# MSPM0G350X register map
Vendor: Texas Instruments; File version: This preliminary header file does not have a version number - build date: 2023-02-21 16:25:48
CPU: CM0 r0p1, little endian, MPU, no FPU, 3 interrupt priority bits
Registers are 32-bit, read-write, reset 0x0 unless marked. A register's access mark holds for its fields unless they carry their own. Offsets are from the block's base; [hi:lo] are bit positions; {n}, {i} and the like mark numbered series; 'fields as' and 'values as' point back to an identical list.

## TIMG0 — PERIPHERALREGION
Base 0x40084000
0x400 FSUB_0 — Subsciber Port 0
  [3:0] FSUB_0_CHANID — 0 = disconnected. 1-15 = connected to channelID = CHANID.
    0=FSUB_0_CHANID_UNCONNECTED (UNCONNECTED)
0x404 FSUB_1 — Subscriber Port 1
  [3:0] FSUB_1_CHANID — 0 = disconnected. 1-15 = connected to channelID = CHANID.
    0=FSUB_1_CHANID_UNCONNECTED (UNCONNECTED)
0x444 FPUB_0 — Publisher Port 0
  [3:0] FPUB_0_CHANID — 0 = disconnected. 1-15 = connected to channelID = CHANID.
    0=FPUB_0_CHANID_UNCONNECTED (UNCONNECTED)
0x448 FPUB_1 — Publisher Port 1
  [3:0] FPUB_1_CHANID — 0 = disconnected. 1-15 = connected to channelID = CHANID.
    0=FPUB_1_CHANID_UNCONNECTED (UNCONNECTED)
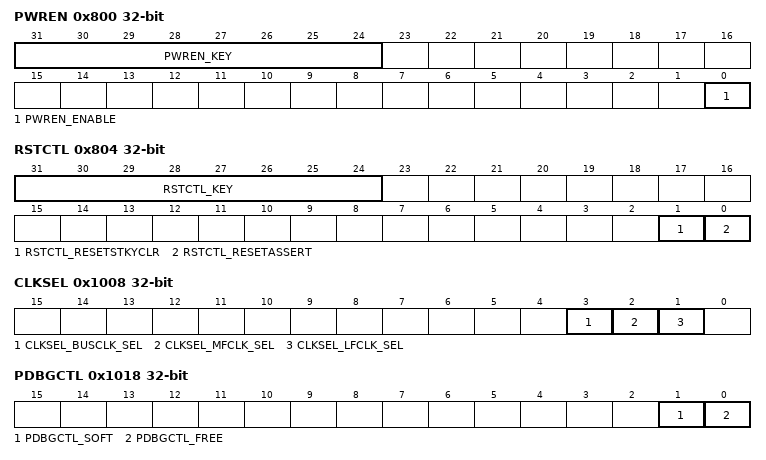
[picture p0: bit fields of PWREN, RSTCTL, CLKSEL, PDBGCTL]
0x800 PWREN — Power enable
  [31:24] PWREN_KEY wo — KEY to allow Power State Change
    38=PWREN_KEY_UNLOCK_W (_TO_UNLOCK_W_)
  [0] PWREN_ENABLE — Enable the power
    0=PWREN_ENABLE_DISABLE (DISABLE); 1=PWREN_ENABLE_ENABLE (ENABLE)
0x804 RSTCTL wo — Reset Control
  [31:24] RSTCTL_KEY — Unlock key
    177=RSTCTL_KEY_UNLOCK_W (_TO_UNLOCK_W_)
  [1] RSTCTL_RESETSTKYCLR — Clear the RESETSTKY bit in the STAT register
    0=RSTCTL_RESETSTKYCLR_NOP (NOP); 1=RSTCTL_RESETSTKYCLR_CLR (CLR)
  [0] RSTCTL_RESETASSERT — Assert reset to the peripheral
    0=RSTCTL_RESETASSERT_NOP (NOP); 1=RSTCTL_RESETASSERT_ASSERT (ASSERT)
0x814 STAT ro — Status Register
  [16] STAT_RESETSTKY — This bit indicates, if the peripheral was reset, since this bit was cleared by RESETSTKYCLR in the RSTCTL register
    0=STAT_RESETSTKY_NORES (NORES); 1=STAT_RESETSTKY_RESET (RESET)
0x1000 CLKDIV — Clock Divider
  [2:0] CLKDIV_RATIO — Selects divide ratio of module clock
    {v}=CLKDIV_RATIO_DIV_BY_{v+1} (DIV_BY_{v+1}) (v=0..7)
0x1008 CLKSEL — Clock Select for Ultra Low Power peripherals
  [3] CLKSEL_BUSCLK_SEL — Selects BUSCLK as clock source if enabled
    0=CLKSEL_BUSCLK_SEL_DISABLE (DISABLE); 1=CLKSEL_BUSCLK_SEL_ENABLE (ENABLE)
  [2] CLKSEL_MFCLK_SEL — Selects MFCLK as clock source if enabled
    0=CLKSEL_MFCLK_SEL_DISABLE (DISABLE); 1=CLKSEL_MFCLK_SEL_ENABLE (ENABLE)
  [1] CLKSEL_LFCLK_SEL — Selects LFCLK as clock source if enabled
    0=CLKSEL_LFCLK_SEL_DISABLE (DISABLE); 1=CLKSEL_LFCLK_SEL_ENABLE (ENABLE)
0x1018 PDBGCTL — Peripheral Debug Control
  [1] PDBGCTL_SOFT — Soft halt boundary control. This function is only available, if [FREE] is set to 'STOP'
    0=PDBGCTL_SOFT_IMMEDIATE (IMMEDIATE); 1=PDBGCTL_SOFT_DELAYED (DELAYED)
  [0] PDBGCTL_FREE — Free run control
    0=PDBGCTL_FREE_STOP (STOP); 1=PDBGCTL_FREE_RUN (RUN)
0x1020 IIDX ro — Interrupt index
  [7:0] IIDX_STAT — Interrupt index status
    0=IIDX_STAT_NO_INTR (NO_INTR); 1=IIDX_STAT_Z (Z); 2=IIDX_STAT_L (L); {v}=IIDX_STAT_CCD{v-5} (CCD{v-5}) (v=5..8); {v}=IIDX_STAT_CCU{v-9} (CCU{v-9}) (v=9..12); 13=IIDX_STAT_CCD4 (CCD4); 14=IIDX_STAT_CCD5 (CCD5); 15=IIDX_STAT_CCU4 (CCU4); 16=IIDX_STAT_CCU5 (CCU5); 25=IIDX_STAT_F (F); 26=IIDX_STAT_TOV (TOV); 27=IIDX_STAT_REPC (REPC); 28=IIDX_STAT_DC (DC); 29=IIDX_STAT_QEIERR (QEIERR)
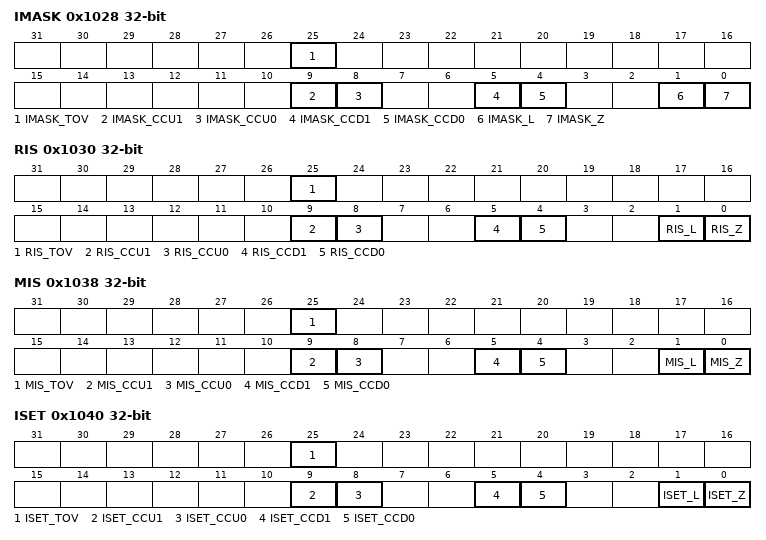
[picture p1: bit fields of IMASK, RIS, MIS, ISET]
0x1028 IMASK — Interrupt mask
  [25] IMASK_TOV — Trigger Overflow Event mask
    0=IMASK_TOV_CLR (CLR); 1=IMASK_TOV_SET (SET)
  [9] IMASK_CCU1 — Capture or Compare UP event mask CCP1
    0=IMASK_CCU1_CLR (CLR); 1=IMASK_CCU1_SET (SET)
  [8] IMASK_CCU0 — Capture or Compare UP event mask CCP0
    0=IMASK_CCU0_CLR (CLR); 1=IMASK_CCU0_SET (SET)
  [5] IMASK_CCD1 — Capture or Compare DN event mask CCP1
    0=IMASK_CCD1_CLR (CLR); 1=IMASK_CCD1_SET (SET)
  [4] IMASK_CCD0 — Capture or Compare DN event mask CCP0
    0=IMASK_CCD0_CLR (CLR); 1=IMASK_CCD0_SET (SET)
  [1] IMASK_L — Load Event mask
    0=IMASK_L_CLR (CLR); 1=IMASK_L_SET (SET)
  [0] IMASK_Z — Zero Event mask
    0=IMASK_Z_CLR (CLR); 1=IMASK_Z_SET (SET)
0x1030 RIS ro — Raw interrupt status
  [25] RIS_TOV — Trigger overflow
    0=RIS_TOV_CLR (CLR); 1=RIS_TOV_SET (SET)
  [9] RIS_CCU1 — Capture or compare up event generated an interrupt CCP1
    0=RIS_CCU1_CLR (CLR); 1=RIS_CCU1_SET (SET)
  [8] RIS_CCU0 — Capture or compare up event generated an interrupt CCP0
    0=RIS_CCU0_CLR (CLR); 1=RIS_CCU0_SET (SET)
  [5] RIS_CCD1 — Capture or compare down event generated an interrupt CCP1
    0=RIS_CCD1_CLR (CLR); 1=RIS_CCD1_SET (SET)
  [4] RIS_CCD0 — Capture or compare down event generated an interrupt CCP0
    0=RIS_CCD0_CLR (CLR); 1=RIS_CCD0_SET (SET)
  [1] RIS_L — Load event generated an interrupt.
    0=RIS_L_CLR (CLR); 1=RIS_L_SET (SET)
  [0] RIS_Z — Zero event generated an interrupt.
    0=RIS_Z_CLR (CLR); 1=RIS_Z_SET (SET)
0x1038 MIS ro — Masked interrupt status
  [25] MIS_TOV — Trigger overflow
    0=MIS_TOV_CLR (CLR); 1=MIS_TOV_SET (SET)
  [9] MIS_CCU1 — Capture or compare up event generated an interrupt CCP1
    0=MIS_CCU1_CLR (CLR); 1=MIS_CCU1_SET (SET)
  [8] MIS_CCU0 — Capture or compare up event generated an interrupt CCP0
    0=MIS_CCU0_CLR (CLR); 1=MIS_CCU0_SET (SET)
  [5] MIS_CCD1 — Capture or compare down event generated an interrupt CCP1
    0=MIS_CCD1_CLR (CLR); 1=MIS_CCD1_SET (SET)
  [4] MIS_CCD0 — Capture or compare down event generated an interrupt CCP0
    0=MIS_CCD0_CLR (CLR); 1=MIS_CCD0_SET (SET)
  [1] MIS_L — Load event generated an interrupt.
    0=MIS_L_CLR (CLR); 1=MIS_L_SET (SET)
  [0] MIS_Z — Zero event generated an interrupt.
    0=MIS_Z_CLR (CLR); 1=MIS_Z_SET (SET)
0x1040 ISET wo — Interrupt set
  [25] ISET_TOV — Trigger Overflow event SET
    0=ISET_TOV_NO_EFFECT (NO_EFFECT); 1=ISET_TOV_SET (SET)
  [9] ISET_CCU1 — Capture or compare up event SET
    0=ISET_CCU1_NO_EFFECT (NO_EFFECT); 1=ISET_CCU1_SET (SET)
  [8] ISET_CCU0 — Capture or compare up event SET
    0=ISET_CCU0_NO_EFFECT (NO_EFFECT); 1=ISET_CCU0_SET (SET)
  [5] ISET_CCD1 — Capture or compare down event SET
    0=ISET_CCD1_NO_EFFECT (NO_EFFECT); 1=ISET_CCD1_SET (SET)
  [4] ISET_CCD0 — Capture or compare down event SET
    0=ISET_CCD0_NO_EFFECT (NO_EFFECT); 1=ISET_CCD0_SET (SET)
  [1] ISET_L — Load event SET
    0=ISET_L_NO_EFFECT (NO_EFFECT); 1=ISET_L_SET (SET)
  [0] ISET_Z — Zero event SET
    0=ISET_Z_NO_EFFECT (NO_EFFECT); 1=ISET_Z_SET (SET)
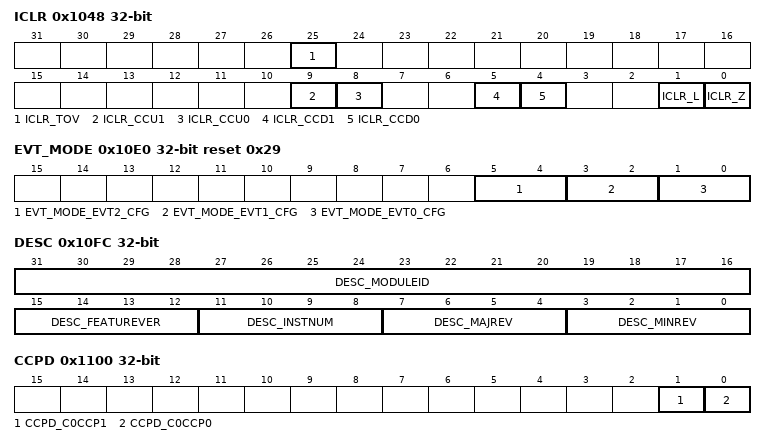
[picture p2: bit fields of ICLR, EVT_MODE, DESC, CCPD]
0x1048 ICLR wo — Interrupt clear
  [25] ICLR_TOV — Trigger Overflow event CLEAR
    0=ICLR_TOV_NO_EFFECT (NO_EFFECT); 1=ICLR_TOV_CLR (CLR)
  [9] ICLR_CCU1 — Capture or compare up event CLEAR
    0=ICLR_CCU1_NO_EFFECT (NO_EFFECT); 1=ICLR_CCU1_CLR (CLR)
  [8] ICLR_CCU0 — Capture or compare up event CLEAR
    0=ICLR_CCU0_NO_EFFECT (NO_EFFECT); 1=ICLR_CCU0_CLR (CLR)
  [5] ICLR_CCD1 — Capture or compare down event CLEAR
    0=ICLR_CCD1_NO_EFFECT (NO_EFFECT); 1=ICLR_CCD1_CLR (CLR)
  [4] ICLR_CCD0 — Capture or compare down event CLEAR
    0=ICLR_CCD0_NO_EFFECT (NO_EFFECT); 1=ICLR_CCD0_CLR (CLR)
  [1] ICLR_L — Load event CLEAR
    0=ICLR_L_NO_EFFECT (NO_EFFECT); 1=ICLR_L_CLR (CLR)
  [0] ICLR_Z — Zero event CLEAR
    0=ICLR_Z_NO_EFFECT (NO_EFFECT); 1=ICLR_Z_CLR (CLR)
0x10E0 EVT_MODE reset 0x29 — Event Mode
  [5:4] EVT_MODE_EVT2_CFG ro — Event line mode select for event corresponding to [IPSTANDARD.INT_EVENT][1]
    0=EVT_MODE_EVT2_CFG_DISABLE (DISABLE); 1=EVT_MODE_EVT2_CFG_SOFTWARE (SOFTWARE); 2=EVT_MODE_EVT2_CFG_HARDWARE (HARDWARE)
  [3:2] EVT_MODE_EVT1_CFG ro — Event line mode select for event corresponding to [IPSTANDARD.INT_EVENT][1]
    0=EVT_MODE_EVT1_CFG_DISABLE (DISABLE); 1=EVT_MODE_EVT1_CFG_SOFTWARE (SOFTWARE); 2=EVT_MODE_EVT1_CFG_HARDWARE (HARDWARE)
  [1:0] EVT_MODE_EVT0_CFG ro — Event line mode select for event corresponding to [IPSTANDARD.INT_EVENT][0]
    0=EVT_MODE_EVT0_CFG_DISABLE (DISABLE); 1=EVT_MODE_EVT0_CFG_SOFTWARE (SOFTWARE); 2=EVT_MODE_EVT0_CFG_HARDWARE (HARDWARE)
0x10FC DESC ro — Module Description
  [31:16] DESC_MODULEID — Module identification contains a unique peripheral identification number. The assignments are maintained in a central database for all of the platform modules to ensure uniqueness.
  [15:12] DESC_FEATUREVER — Feature Set for the module *instance*
  [11:8] DESC_INSTNUM — Instance Number within the device. This will be a parameter to the RTL for modules that can have multiple instances
  [7:4] DESC_MAJREV — Major rev of the IP
  [3:0] DESC_MINREV — Minor rev of the IP
0x1100 CCPD — CCP Direction
  [1] CCPD_C0CCP1 — Counter CCP1
    0=CCPD_C0CCP1_INPUT (INPUT); 1=CCPD_C0CCP1_OUTPUT (OUTPUT)
  [0] CCPD_C0CCP0 — Counter CCP0
    0=CCPD_C0CCP0_INPUT (INPUT); 1=CCPD_C0CCP0_OUTPUT (OUTPUT)
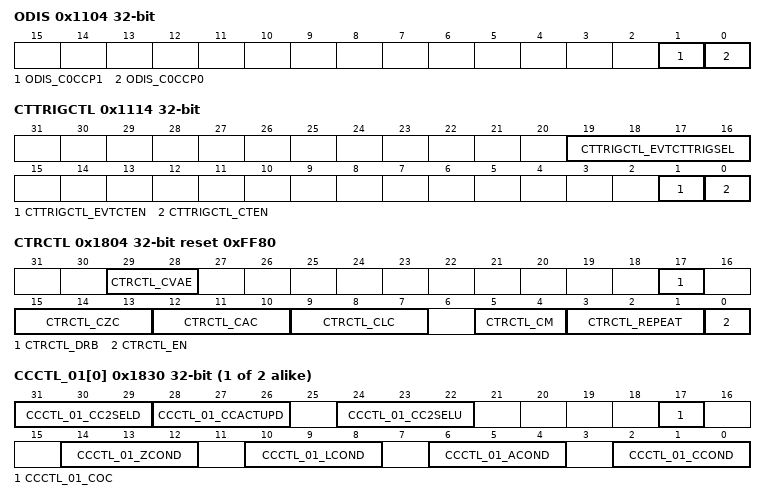
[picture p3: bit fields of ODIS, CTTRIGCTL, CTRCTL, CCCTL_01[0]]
0x1104 ODIS — Output Disable
  [1] ODIS_C0CCP1 — Counter CCP1 Disable Mask Defines whether CCP0 of Counter n is forced low or not
    0=ODIS_C0CCP1_CCP_OUTPUT_OCTL (CCP_OUTPUT_OCTL); 1=ODIS_C0CCP1_CCP_OUTPUT_LOW (CCP_OUTPUT_LOW)
  [0] ODIS_C0CCP0 — Counter CCP0 Disable Mask Defines whether CCP0 of Counter n is forced low or not
    0=ODIS_C0CCP0_CCP_OUTPUT_OCTL (CCP_OUTPUT_OCTL); 1=ODIS_C0CCP0_CCP_OUTPUT_LOW (CCP_OUTPUT_LOW)
0x1108 CCLKCTL — Counter Clock Control Register
  [0] CCLKCTL_CLKEN — Clock Enable Disables the clock gating to the module. SW has to explicitly program the value to 0 to gate the clock.
    0=CCLKCTL_CLKEN_DISABLED (DISABLED); 1=CCLKCTL_CLKEN_ENABLED (ENABLED)
0x110C CPS — Clock Prescale Register
  [7:0] CPS_PCNT — Pre-Scale Count This field specifies the pre-scale count value. The selected TIMCLK source is divided by a value of (PCNT+1). A PCNT value of 0 divides TIMCLK by 1, effectively bypassing the divider. A PCNT value of greater than 0 divides the TIMCLK source generating a slower clock
0x1110 CPSV ro — Clock prescale count status register
  [7:0] CPSV_CPSVAL — Current Prescale Count Value
0x1114 CTTRIGCTL — Timer Cross Trigger Control Register
  [19:16] CTTRIGCTL_EVTCTTRIGSEL — Used to Select the subscriber port that should be used for input cross trigger. Refer Figure 8 Cross Trigger Generation Path
    0=CTTRIGCTL_EVTCTTRIGSEL_FSUB0 (FSUB0); 1=CTTRIGCTL_EVTCTTRIGSEL_FSUB1 (FSUB1); 2=CTTRIGCTL_EVTCTTRIGSEL_Z (Z); 3=CTTRIGCTL_EVTCTTRIGSEL_L (L); {v}=CTTRIGCTL_EVTCTTRIGSEL_CCD{v-4} (CCD{v-4}) (v=4..7); {v}=CTTRIGCTL_EVTCTTRIGSEL_CCU{v-8} (CCU{v-8}) (v=8..11)
  [1] CTTRIGCTL_EVTCTEN — Enable the Input Trigger Conditions to the Timer module as a condition for Cross Triggers. Refer Figure 8 Cross Trigger Generation Path
    0=CTTRIGCTL_EVTCTEN_DISABLED (DISABLED); 1=CTTRIGCTL_EVTCTEN_ENABLE (ENABLE)
  [0] CTTRIGCTL_CTEN — Timer Cross trigger enable. This field is used to enable whether the SW or HW logic can generate a timer cross trigger event in the system. These cross triggers are connected to the respective timer trigger in of the other timer IPs in the SOC power domain. The timer cross trigger is essentially the combined logic of the HW and SW conditions controlling EN bit in the CTRCTL register.
    0=CTTRIGCTL_CTEN_DISABLED (DISABLED); 1=CTTRIGCTL_CTEN_ENABLE (ENABLE)
0x111C CTTRIG wo — Timer Cross Trigger Register
  [0] CTTRIG_TRIG — Generate Cross Trigger This bit when programmed will generate a synchronized trigger condition all the cross trigger enabled Timer instances including current timer instance.
    0=CTTRIG_TRIG_DISABLED (DISABLED); 1=CTTRIG_TRIG_GENERATE (GENERATE)
0x1800 CTR — Counter Register
  [15:0] CTR_CCTR — Current Counter value
0x1804 CTRCTL reset 0xFF80 — Counter Control Register
  [29:28] CTRCTL_CVAE — Counter Value After Enable. This field specifies the initialization condition of the counter when the EN bit is changed from 0 to 1 by a write to the CTRCTL register. Note that an external event can also cause the EN bit to go active.
    0=CTRCTL_CVAE_LDVAL (LDVAL); 1=CTRCTL_CVAE_NOCHANGE (NOCHANGE); 2=CTRCTL_CVAE_ZEROVAL (ZEROVAL)
  [17] CTRCTL_DRB — Debug Resume Behavior This bit specifies what the device does following the release/exit of debug mode.
    0=CTRCTL_DRB_RESUME (RESUME); 1=CTRCTL_DRB_CVAE_ACTION (CVAE_ACTION)
  [15:13] CTRCTL_CZC — Counter Zero Control This field specifies what controls the counter operation with respect to zeroing the counter value. Encodings 1-3 are present based on the CCPC parameter value. Bits 4-5 are present based on the HQEI parameter value. Any encodings not provided are documented as reserved.
    {v}=CTRCTL_CZC_CCCTL{v}_ZCOND (CCCTL{v}_ZCOND) (v=0..3); 4=CTRCTL_CZC_QEI_2INP (QEI_2INP); 5=CTRCTL_CZC_QEI_3INP (QEI_3INP)
  [12:10] CTRCTL_CAC — Counter Advance Control. This field specifies what controls the counter operation with respect to advancing (incrementing or decrementing) the counter value. Encodings 1-3 are present based on the CCPC parameter value. Bits 4-5 are present based on the HQEI parameter value. Any encodings not provided are documented as reserved.
    {v}=CTRCTL_CAC_CCCTL{v}_ACOND (CCCTL{v}_ACOND) (v=0..3); 4=CTRCTL_CAC_QEI_2INP (QEI_2INP); 5=CTRCTL_CAC_QEI_3INP (QEI_3INP)
  [9:7] CTRCTL_CLC — Counter Load Control. This field specifies what controls the counter operation with respect to setting the counter to the LD register value. Encodings 1-3 are present based on the CCPC parameter value. Bits 4-5 are present based on the HQEI parameter value. Any encodings not provided are documented as reserved.
    {v}=CTRCTL_CLC_CCCTL{v}_LCOND (CCCTL{v}_LCOND) (v=0..3); 4=CTRCTL_CLC_QEI_2INP (QEI_2INP); 5=CTRCTL_CLC_QEI_3INP (QEI_3INP)
  [5:4] CTRCTL_CM — Count Mode
    0=CTRCTL_CM_DOWN (DOWN); 1=CTRCTL_CM_UP_DOWN (UP_DOWN); 2=CTRCTL_CM_UP (UP)
  [3:1] CTRCTL_REPEAT — Repeat. The repeat bit controls whether the counter continues to advance following a zero event, or the exiting of a debug or fault condition. If counting down, a zero event is followed by a load at the next advance condition. If counting up-down, a zero event is followed by an advance event (+1). The intent of encoding 3 is that if the debug condition is in effect, the generation of the load pulse is deferred until the debug condition is over. This allows the counter to reach zero before counting is suspended.
    {v}=CTRCTL_REPEAT_REPEAT_{v} (REPEAT_{v}) (v=0..4)
  [0] CTRCTL_EN — Counter Enable. This bit allows the timer to advance This bit is automatically cleared if REPEAT=0 (do not automatically reload) and the counter value equals zero. CPU Write: A register write that sets the EN bit, the counter value is set per the CVAE value. Hardware: This bit may also be set as the result of an LCOND or ZCOND condition being met and the counter value changed to the load value or zero value, respectively.
    0=CTRCTL_EN_DISABLED (DISABLED); 1=CTRCTL_EN_ENABLED (ENABLED)
0x1808 LOAD
  [15:0] LOAD_LD — Load Value
{0x1810+4i} CC_01[{i}] (i=0..1) — Capture or Compare Register 0 to Capture or Compare Register 1
  [15:0] CC_01_CCVAL — Capture or compare value
{0x1830+4i} CCCTL_01[{i}] (i=0..1) — Capture or Compare Control Registers
  [31:29] CCCTL_01_CC2SELD — Selects the source second CCD event.
    {v}=CCCTL_01_CC2SELD_SEL_CCD{v} (SEL_CCD{v}) (v=0..5)
  [28:26] CCCTL_01_CCACTUPD — CCACT shadow register Update Method This field controls how updates to the CCCACT shadow register are performed
    0=CCCTL_01_CCACTUPD_IMMEDIATELY (IMMEDIATELY); 1=CCCTL_01_CCACTUPD_ZERO_EVT (ZERO_EVT); 2=CCCTL_01_CCACTUPD_COMPARE_DOWN_EVT (COMPARE_DOWN_EVT); 3=CCCTL_01_CCACTUPD_COMPARE_UP_EVT (COMPARE_UP_EVT); 4=CCCTL_01_CCACTUPD_ZERO_LOAD_EVT (ZERO_LOAD_EVT); 5=CCCTL_01_CCACTUPD_ZERO_RC_ZERO_EVT (ZERO_RC_ZERO_EVT); 6=CCCTL_01_CCACTUPD_TRIG (TRIG)
  [24:22] CCCTL_01_CC2SELU — Selects the source second CCU event.
    {v}=CCCTL_01_CC2SELU_SEL_CCU{v} (SEL_CCU{v}) (v=0..5)
  [17] CCCTL_01_COC — Capture or Compare. #br# Specifies whether the corresponding CC register is used as a capture register or a compare register (never both).
    0=CCCTL_01_COC_COMPARE (COMPARE); 1=CCCTL_01_COC_CAPTURE (CAPTURE)
  [14:12] CCCTL_01_ZCOND — Zero Condition. #br# This field specifies the condition that generates a zero pulse. 4h-Fh = Reserved
    1=CCCTL_01_ZCOND_CC_TRIG_RISE (CC_TRIG_RISE); 2=CCCTL_01_ZCOND_CC_TRIG_FALL (CC_TRIG_FALL); 3=CCCTL_01_ZCOND_CC_TRIG_EDGE (CC_TRIG_EDGE)
  [10:8] CCCTL_01_LCOND — Load Condition. #br# Specifies the condition that generates a load pulse. 4h-Fh = Reserved
    1=CCCTL_01_LCOND_CC_TRIG_RISE (CC_TRIG_RISE); 2=CCCTL_01_LCOND_CC_TRIG_FALL (CC_TRIG_FALL); 3=CCCTL_01_LCOND_CC_TRIG_EDGE (CC_TRIG_EDGE)
  [6:4] CCCTL_01_ACOND — Advance Condition. #br# Specifies the condition that generates an advance pulse. 6h-Fh = Reserved
    0=CCCTL_01_ACOND_TIMCLK (TIMCLK); 1=CCCTL_01_ACOND_CC_TRIG_RISE (CC_TRIG_RISE); 2=CCCTL_01_ACOND_CC_TRIG_FALL (CC_TRIG_FALL); 3=CCCTL_01_ACOND_CC_TRIG_EDGE (CC_TRIG_EDGE); 5=CCCTL_01_ACOND_CC_TRIG_HIGH (CC_TRIG_HIGH)
  [2:0] CCCTL_01_CCOND — Capture Condition. #br# Specifies the condition that generates a capture pulse. 4h-Fh = Reserved
    0=CCCTL_01_CCOND_NOCAPTURE (NOCAPTURE); 1=CCCTL_01_CCOND_CC_TRIG_RISE (CC_TRIG_RISE); 2=CCCTL_01_CCOND_CC_TRIG_FALL (CC_TRIG_FALL); 3=CCCTL_01_CCOND_CC_TRIG_EDGE (CC_TRIG_EDGE)
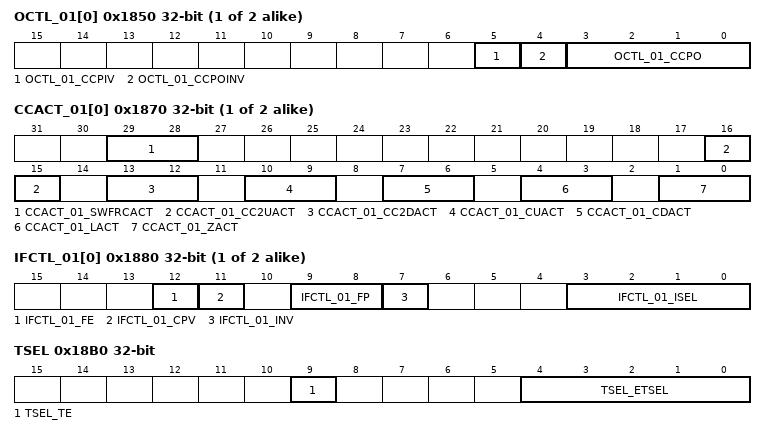
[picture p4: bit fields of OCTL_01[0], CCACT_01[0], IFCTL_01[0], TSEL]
{0x1850+4i} OCTL_01[{i}] (i=0..1) — CCP Output Control Registers
  [5] OCTL_01_CCPIV — CCP Initial Value This bit specifies the logical value put on the signal generator state while the counter is disabled (CTRCTL.EN == 0).
    0=OCTL_01_CCPIV_LOW (LOW); 1=OCTL_01_CCPIV_HIGH (HIGH)
  [4] OCTL_01_CCPOINV — CCP Output Invert The output as selected by CCPO is conditionally inverted.
    0=OCTL_01_CCPOINV_NOINV (NOINV); 1=OCTL_01_CCPOINV_INV (INV)
  [3:0] OCTL_01_CCPO — CCP Output Source
    0=OCTL_01_CCPO_FUNCVAL (FUNCVAL); 1=OCTL_01_CCPO_LOAD (LOAD); 2=OCTL_01_CCPO_CMPVAL (CMPVAL); 4=OCTL_01_CCPO_ZERO (ZERO); 5=OCTL_01_CCPO_CAPCOND (CAPCOND); 6=OCTL_01_CCPO_FAULTCOND (FAULTCOND); 8=OCTL_01_CCPO_CC0_MIRROR_ALL (CC0_MIRROR_ALL); 9=OCTL_01_CCPO_CC1_MIRROR_ALL (CC1_MIRROR_ALL); 12=OCTL_01_CCPO_DEADBAND (DEADBAND); 13=OCTL_01_CCPO_CNTDIR (CNTDIR)
{0x1870+4i} CCACT_01[{i}] (i=0..1) — Capture or Compare Action Registers
  [29:28] CCACT_01_SWFRCACT — CCP Output Action on Software Froce Output This field describes the resulting action of software force. This action has a shadow register, which will be updated under specific condition. So that this register cannot take into effect immediately.
    0=CCACT_01_SWFRCACT_DISABLED (DISABLED); 1=CCACT_01_SWFRCACT_CCP_HIGH (CCP_HIGH); 2=CCACT_01_SWFRCACT_CCP_LOW (CCP_LOW)
  [16:15] CCACT_01_CC2UACT — CCP Output Action on CC2U event.
    0=CCACT_01_CC2UACT_DISABLED (DISABLED); 1=CCACT_01_CC2UACT_CCP_HIGH (CCP_HIGH); 2=CCACT_01_CC2UACT_CCP_LOW (CCP_LOW); 3=CCACT_01_CC2UACT_CCP_TOGGLE (CCP_TOGGLE)
  [13:12] CCACT_01_CC2DACT — CCP Output Action on CC2D event.
    0=CCACT_01_CC2DACT_DISABLED (DISABLED); 1=CCACT_01_CC2DACT_CCP_HIGH (CCP_HIGH); 2=CCACT_01_CC2DACT_CCP_LOW (CCP_LOW); 3=CCACT_01_CC2DACT_CCP_TOGGLE (CCP_TOGGLE)
  [10:9] CCACT_01_CUACT — CCP Output Action on Compare (Up) This field describes the resulting action of the signal generator upon detecting a compare event while counting up.
    0=CCACT_01_CUACT_DISABLED (DISABLED); 1=CCACT_01_CUACT_CCP_HIGH (CCP_HIGH); 2=CCACT_01_CUACT_CCP_LOW (CCP_LOW); 3=CCACT_01_CUACT_CCP_TOGGLE (CCP_TOGGLE)
  [7:6] CCACT_01_CDACT — CCP Output Action on Compare (Down) This field describes the resulting action of the signal generator upon detecting a compare event while counting down.
    0=CCACT_01_CDACT_DISABLED (DISABLED); 1=CCACT_01_CDACT_CCP_HIGH (CCP_HIGH); 2=CCACT_01_CDACT_CCP_LOW (CCP_LOW); 3=CCACT_01_CDACT_CCP_TOGGLE (CCP_TOGGLE)
  [4:3] CCACT_01_LACT — CCP Output Action on Load Specifies what changes occur to CCP output as the result of a load event.
    0=CCACT_01_LACT_DISABLED (DISABLED); 1=CCACT_01_LACT_CCP_HIGH (CCP_HIGH); 2=CCACT_01_LACT_CCP_LOW (CCP_LOW); 3=CCACT_01_LACT_CCP_TOGGLE (CCP_TOGGLE)
  [1:0] CCACT_01_ZACT — CCP Output Action on Zero Specifies what changes occur to CCP output as the result of a zero event.
    0=CCACT_01_ZACT_DISABLED (DISABLED); 1=CCACT_01_ZACT_CCP_HIGH (CCP_HIGH); 2=CCACT_01_ZACT_CCP_LOW (CCP_LOW); 3=CCACT_01_ZACT_CCP_TOGGLE (CCP_TOGGLE)
{0x1880+4i} IFCTL_01[{i}] (i=0..1) — Input Filter Control Register
  [12] IFCTL_01_FE — Filter Enable This bit controls whether the input is filtered by the input filter or bypasses to the edge detect.
    0=IFCTL_01_FE_DISABLED (DISABLED); 1=IFCTL_01_FE_ENABLED (ENABLED)
  [11] IFCTL_01_CPV — Consecutive Period/Voting Select This bit controls whether the input filter uses a stricter consecutive period count or majority voting.
    0=IFCTL_01_CPV_CONSECUTIVE (CONSECUTIVE); 1=IFCTL_01_CPV_VOTING (VOTING)
  [9:8] IFCTL_01_FP — Filter Period. This field specifies the sample period for the input filter. I.e. The input is sampled for FP timer clocks during filtering.
    0=IFCTL_01_FP__3 (_3); 1=IFCTL_01_FP__5 (_5); 2=IFCTL_01_FP__8 (_8)
  [7] IFCTL_01_INV — Input Inversion This bit controls whether the selected input is inverted.
    0=IFCTL_01_INV_NOINVERT (NOINVERT); 1=IFCTL_01_INV_INVERT (INVERT)
  [3:0] IFCTL_01_ISEL — Input Select (CCP0) This field selects the input source to the filter input. 4h-7h = Reserved
    0=IFCTL_01_ISEL_CCPX_INPUT (CCPX_INPUT); 1=IFCTL_01_ISEL_CCPX_INPUT_PAIR (CCPX_INPUT_PAIR); 2=IFCTL_01_ISEL_CCP0_INPUT (CCP0_INPUT); 3=IFCTL_01_ISEL_TRIG_INPUT (TRIG_INPUT); 4=IFCTL_01_ISEL_CCP_XOR (CCP_XOR); 5=IFCTL_01_ISEL_FSUB0 (FSUB0); 6=IFCTL_01_ISEL_FSUB1 (FSUB1); 7=IFCTL_01_ISEL_COMP0 (COMP0); 8=IFCTL_01_ISEL_COMP1 (COMP1); 9=IFCTL_01_ISEL_COMP2 (COMP2)
0x18B0 TSEL — Trigger Select
  [9] TSEL_TE — Trigger Enable. This selects whether a trigger is enabled or not for this counter 0x0 = Triggers are not used 0x1 = Triggers are used as selected by the ETSEL field
    0=TSEL_TE_DISABLED (DISABLED); 1=TSEL_TE_ENABLED (ENABLED)
  [4:0] TSEL_ETSEL — External Trigger Select. #br# This selects which System Event is used if the input filter selects trigger. Triggers 0-15 are used to connect triggers generated by other timer modules in the same power domain. Refer to the SoC datasheet to get details. Triggers 16 and 17 are connected to event manager subscriber ports. Event lines 18-31 are reserved for future use.
    {v}=TSEL_ETSEL_TRIG{v} (TRIG{v}) (v=0..15); 16=TSEL_ETSEL_TRIG_SUB0 (TRIG_SUB0); 17=TSEL_ETSEL_TRIG_SUB1 (TRIG_SUB1)

## TIMG12 — PERIPHERALREGION
Base 0x40870000
Registers as TIMG0, without CPS, CPSV; these are added or differ:
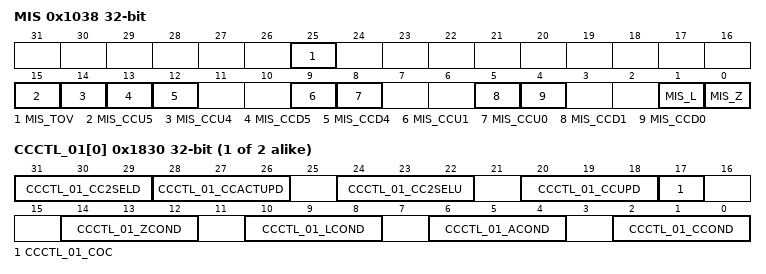
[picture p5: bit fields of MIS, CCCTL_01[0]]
0x1038 MIS ro — Masked interrupt status
  [25] MIS_TOV — Trigger overflow
    0=MIS_TOV_CLR (CLR); 1=MIS_TOV_SET (SET)
  [15] MIS_CCU5 — Compare up event generated an interrupt CCP5
    0=MIS_CCU5_CLR (CLR); 1=MIS_CCU5_SET (SET)
  [14] MIS_CCU4 — Compare up event generated an interrupt CCP4
    0=MIS_CCU4_CLR (CLR); 1=MIS_CCU4_SET (SET)
  [13] MIS_CCD5 — Compare down event generated an interrupt CCP5
    0=MIS_CCD5_CLR (CLR); 1=MIS_CCD5_SET (SET)
  [12] MIS_CCD4 — Compare down event generated an interrupt CCP4
    0=MIS_CCD4_CLR (CLR); 1=MIS_CCD4_SET (SET)
  [9] MIS_CCU1 — Capture or compare up event generated an interrupt CCP1
    0=MIS_CCU1_CLR (CLR); 1=MIS_CCU1_SET (SET)
  [8] MIS_CCU0 — Capture or compare up event generated an interrupt CCP0
    0=MIS_CCU0_CLR (CLR); 1=MIS_CCU0_SET (SET)
  [5] MIS_CCD1 — Capture or compare down event generated an interrupt CCP1
    0=MIS_CCD1_CLR (CLR); 1=MIS_CCD1_SET (SET)
  [4] MIS_CCD0 — Capture or compare down event generated an interrupt CCP0
    0=MIS_CCD0_CLR (CLR); 1=MIS_CCD0_SET (SET)
  [1] MIS_L — Load event generated an interrupt.
    0=MIS_L_CLR (CLR); 1=MIS_L_SET (SET)
  [0] MIS_Z — Zero event generated an interrupt.
    0=MIS_Z_CLR (CLR); 1=MIS_Z_SET (SET)
0x1800 CTR — Counter Register
  [31:0] CTR_CCTR — Current Counter value
0x1808 LOAD
  [31:0] LOAD_LD — Load Value
{0x1810+4i} CC_01[{i}] (i=0..1) — Capture or Compare Register 0 to Capture or Compare Register 1
  [31:0] CC_01_CCVAL — Capture or compare value
{0x1830+4i} CCCTL_01[{i}] (i=0..1) — Capture or Compare Control Registers
  [31:29] CCCTL_01_CC2SELD — Selects the source second CCD event.
    {v}=CCCTL_01_CC2SELD_SEL_CCD{v} (SEL_CCD{v}) (v=0..5)
  [28:26] CCCTL_01_CCACTUPD — CCACT shadow register Update Method This field controls how updates to the CCCACT shadow register are performed
    values as TIMG0.CCCTL_01[0].CCCTL_01_CCACTUPD
  [24:22] CCCTL_01_CC2SELU — Selects the source second CCU event.
    {v}=CCCTL_01_CC2SELU_SEL_CCU{v} (SEL_CCU{v}) (v=0..5)
  [20:18] CCCTL_01_CCUPD — Capture and Compare Update Method This field controls how updates to the pipelined capture and compare register are performed (when operating in compare mode, COC=0).
    0=CCCTL_01_CCUPD_IMMEDIATELY (IMMEDIATELY); 1=CCCTL_01_CCUPD_ZERO_EVT (ZERO_EVT); 2=CCCTL_01_CCUPD_COMPARE_DOWN_EVT (COMPARE_DOWN_EVT); 3=CCCTL_01_CCUPD_COMPARE_UP_EVT (COMPARE_UP_EVT); 4=CCCTL_01_CCUPD_ZERO_LOAD_EVT (ZERO_LOAD_EVT); 5=CCCTL_01_CCUPD_ZERO_RC_ZERO_EVT (ZERO_RC_ZERO_EVT); 6=CCCTL_01_CCUPD_TRIG (TRIG)
  [17] CCCTL_01_COC — Capture or Compare. #br# Specifies whether the corresponding CC register is used as a capture register or a compare register (never both).
    0=CCCTL_01_COC_COMPARE (COMPARE); 1=CCCTL_01_COC_CAPTURE (CAPTURE)
  [14:12] CCCTL_01_ZCOND — Zero Condition. #br# This field specifies the condition that generates a zero pulse. 4h-Fh = Reserved
    1=CCCTL_01_ZCOND_CC_TRIG_RISE (CC_TRIG_RISE); 2=CCCTL_01_ZCOND_CC_TRIG_FALL (CC_TRIG_FALL); 3=CCCTL_01_ZCOND_CC_TRIG_EDGE (CC_TRIG_EDGE)
  [10:8] CCCTL_01_LCOND — Load Condition. #br# Specifies the condition that generates a load pulse. 4h-Fh = Reserved
    1=CCCTL_01_LCOND_CC_TRIG_RISE (CC_TRIG_RISE); 2=CCCTL_01_LCOND_CC_TRIG_FALL (CC_TRIG_FALL); 3=CCCTL_01_LCOND_CC_TRIG_EDGE (CC_TRIG_EDGE)
  [6:4] CCCTL_01_ACOND — Advance Condition. #br# Specifies the condition that generates an advance pulse. 6h-Fh = Reserved
    values as TIMG0.CCCTL_01[0].CCCTL_01_ACOND
  [2:0] CCCTL_01_CCOND — Capture Condition. #br# Specifies the condition that generates a capture pulse. 4h-Fh = Reserved
    0=CCCTL_01_CCOND_NOCAPTURE (NOCAPTURE); 1=CCCTL_01_CCOND_CC_TRIG_RISE (CC_TRIG_RISE); 2=CCCTL_01_CCOND_CC_TRIG_FALL (CC_TRIG_FALL); 3=CCCTL_01_CCOND_CC_TRIG_EDGE (CC_TRIG_EDGE)

## TIMG6 — PERIPHERALREGION
Base 0x40868000
Same registers: TIMG7 0x4086A000
Registers as TIMG12; these are added or differ:
0x110C CPS — Clock Prescale Register
  fields as TIMG0.CPS
0x1110 CPSV ro — Clock prescale count status register
  [7:0] CPSV_CPSVAL — Current Prescale Count Value
0x1124 GCTL — Shadow to active load mask
  [0] GCTL_SHDWLDEN — Enables shadow to active load of bufferred registers and register fields.
    0=GCTL_SHDWLDEN_DISABLE (DISABLE); 1=GCTL_SHDWLDEN_ENABLE (ENABLE)
0x1800 CTR — Counter Register
  [15:0] CTR_CCTR — Current Counter value
0x1808 LOAD
  [15:0] LOAD_LD — Load Value
{0x1810+4i} CC_01[{i}] (i=0..1) — Capture or Compare Register 0 to Capture or Compare Register 1
  [15:0] CC_01_CCVAL — Capture or compare value

## TIMG8 — PERIPHERALREGION
Base 0x40090000
Registers as TIMG0; these are added or differ:
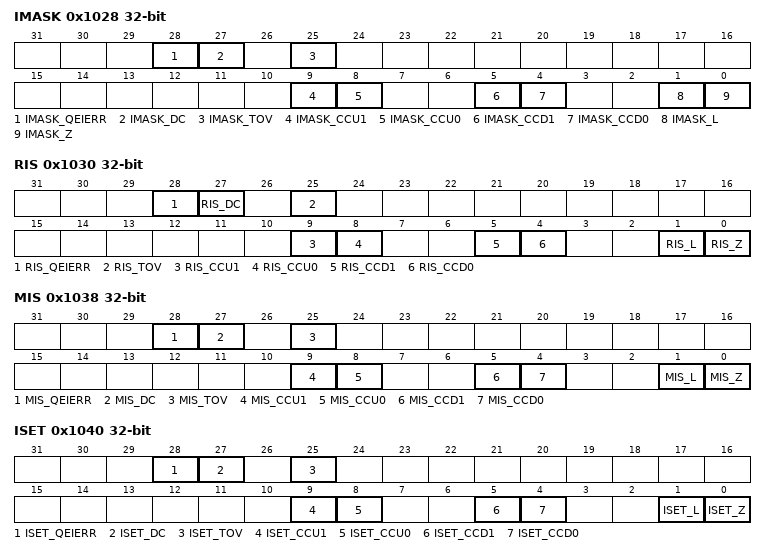
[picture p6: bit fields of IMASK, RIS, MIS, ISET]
0x1028 IMASK — Interrupt mask
  [28] IMASK_QEIERR — QEIERR Event mask
    0=IMASK_QEIERR_CLR (CLR); 1=IMASK_QEIERR_SET (SET)
  [27] IMASK_DC — Direction Change Event mask
    0=IMASK_DC_CLR (CLR); 1=IMASK_DC_SET (SET)
  [25] IMASK_TOV — Trigger Overflow Event mask
    0=IMASK_TOV_CLR (CLR); 1=IMASK_TOV_SET (SET)
  [9] IMASK_CCU1 — Capture or Compare UP event mask CCP1
    0=IMASK_CCU1_CLR (CLR); 1=IMASK_CCU1_SET (SET)
  [8] IMASK_CCU0 — Capture or Compare UP event mask CCP0
    0=IMASK_CCU0_CLR (CLR); 1=IMASK_CCU0_SET (SET)
  [5] IMASK_CCD1 — Capture or Compare DN event mask CCP1
    0=IMASK_CCD1_CLR (CLR); 1=IMASK_CCD1_SET (SET)
  [4] IMASK_CCD0 — Capture or Compare DN event mask CCP0
    0=IMASK_CCD0_CLR (CLR); 1=IMASK_CCD0_SET (SET)
  [1] IMASK_L — Load Event mask
    0=IMASK_L_CLR (CLR); 1=IMASK_L_SET (SET)
  [0] IMASK_Z — Zero Event mask
    0=IMASK_Z_CLR (CLR); 1=IMASK_Z_SET (SET)
0x1030 RIS ro — Raw interrupt status
  [28] RIS_QEIERR — QEIERR, set on an incorrect state transition on the encoder interface.
    0=RIS_QEIERR_CLR (CLR); 1=RIS_QEIERR_SET (SET)
  [27] RIS_DC — Direction Change
    0=RIS_DC_CLR (CLR); 1=RIS_DC_SET (SET)
  [25] RIS_TOV — Trigger overflow
    0=RIS_TOV_CLR (CLR); 1=RIS_TOV_SET (SET)
  [9] RIS_CCU1 — Capture or compare up event generated an interrupt CCP1
    0=RIS_CCU1_CLR (CLR); 1=RIS_CCU1_SET (SET)
  [8] RIS_CCU0 — Capture or compare up event generated an interrupt CCP0
    0=RIS_CCU0_CLR (CLR); 1=RIS_CCU0_SET (SET)
  [5] RIS_CCD1 — Capture or compare down event generated an interrupt CCP1
    0=RIS_CCD1_CLR (CLR); 1=RIS_CCD1_SET (SET)
  [4] RIS_CCD0 — Capture or compare down event generated an interrupt CCP0
    0=RIS_CCD0_CLR (CLR); 1=RIS_CCD0_SET (SET)
  [1] RIS_L — Load event generated an interrupt.
    0=RIS_L_CLR (CLR); 1=RIS_L_SET (SET)
  [0] RIS_Z — Zero event generated an interrupt.
    0=RIS_Z_CLR (CLR); 1=RIS_Z_SET (SET)
0x1038 MIS ro — Masked interrupt status
  [28] MIS_QEIERR — QEIERR
    0=MIS_QEIERR_CLR (CLR); 1=MIS_QEIERR_SET (SET)
  [27] MIS_DC — Direction Change
    0=MIS_DC_CLR (CLR); 1=MIS_DC_SET (SET)
  [25] MIS_TOV — Trigger overflow
    0=MIS_TOV_CLR (CLR); 1=MIS_TOV_SET (SET)
  [9] MIS_CCU1 — Capture or compare up event generated an interrupt CCP1
    0=MIS_CCU1_CLR (CLR); 1=MIS_CCU1_SET (SET)
  [8] MIS_CCU0 — Capture or compare up event generated an interrupt CCP0
    0=MIS_CCU0_CLR (CLR); 1=MIS_CCU0_SET (SET)
  [5] MIS_CCD1 — Capture or compare down event generated an interrupt CCP1
    0=MIS_CCD1_CLR (CLR); 1=MIS_CCD1_SET (SET)
  [4] MIS_CCD0 — Capture or compare down event generated an interrupt CCP0
    0=MIS_CCD0_CLR (CLR); 1=MIS_CCD0_SET (SET)
  [1] MIS_L — Load event generated an interrupt.
    0=MIS_L_CLR (CLR); 1=MIS_L_SET (SET)
  [0] MIS_Z — Zero event generated an interrupt.
    0=MIS_Z_CLR (CLR); 1=MIS_Z_SET (SET)
0x1040 ISET wo — Interrupt set
  [28] ISET_QEIERR — QEIERR event SET
    0=ISET_QEIERR_NO_EFFECT (NO_EFFECT); 1=ISET_QEIERR_SET (SET)
  [27] ISET_DC — Direction Change event SET
    0=ISET_DC_NO_EFFECT (NO_EFFECT); 1=ISET_DC_SET (SET)
  [25] ISET_TOV — Trigger Overflow event SET
    0=ISET_TOV_NO_EFFECT (NO_EFFECT); 1=ISET_TOV_SET (SET)
  [9] ISET_CCU1 — Capture or compare up event SET
    0=ISET_CCU1_NO_EFFECT (NO_EFFECT); 1=ISET_CCU1_SET (SET)
  [8] ISET_CCU0 — Capture or compare up event SET
    0=ISET_CCU0_NO_EFFECT (NO_EFFECT); 1=ISET_CCU0_SET (SET)
  [5] ISET_CCD1 — Capture or compare down event SET
    0=ISET_CCD1_NO_EFFECT (NO_EFFECT); 1=ISET_CCD1_SET (SET)
  [4] ISET_CCD0 — Capture or compare down event SET
    0=ISET_CCD0_NO_EFFECT (NO_EFFECT); 1=ISET_CCD0_SET (SET)
  [1] ISET_L — Load event SET
    0=ISET_L_NO_EFFECT (NO_EFFECT); 1=ISET_L_SET (SET)
  [0] ISET_Z — Zero event SET
    0=ISET_Z_NO_EFFECT (NO_EFFECT); 1=ISET_Z_SET (SET)
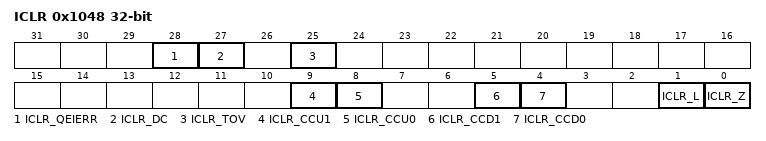
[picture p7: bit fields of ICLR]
0x1048 ICLR wo — Interrupt clear
  [28] ICLR_QEIERR — QEIERR event CLEAR
    0=ICLR_QEIERR_NO_EFFECT (NO_EFFECT); 1=ICLR_QEIERR_CLR (CLR)
  [27] ICLR_DC — Direction Change event CLEAR
    0=ICLR_DC_NO_EFFECT (NO_EFFECT); 1=ICLR_DC_CLR (CLR)
  [25] ICLR_TOV — Trigger Overflow event CLEAR
    0=ICLR_TOV_NO_EFFECT (NO_EFFECT); 1=ICLR_TOV_CLR (CLR)
  [9] ICLR_CCU1 — Capture or compare up event CLEAR
    0=ICLR_CCU1_NO_EFFECT (NO_EFFECT); 1=ICLR_CCU1_CLR (CLR)
  [8] ICLR_CCU0 — Capture or compare up event CLEAR
    0=ICLR_CCU0_NO_EFFECT (NO_EFFECT); 1=ICLR_CCU0_CLR (CLR)
  [5] ICLR_CCD1 — Capture or compare down event CLEAR
    0=ICLR_CCD1_NO_EFFECT (NO_EFFECT); 1=ICLR_CCD1_CLR (CLR)
  [4] ICLR_CCD0 — Capture or compare down event CLEAR
    0=ICLR_CCD0_NO_EFFECT (NO_EFFECT); 1=ICLR_CCD0_CLR (CLR)
  [1] ICLR_L — Load event CLEAR
    0=ICLR_L_NO_EFFECT (NO_EFFECT); 1=ICLR_L_CLR (CLR)
  [0] ICLR_Z — Zero event CLEAR
    0=ICLR_Z_NO_EFFECT (NO_EFFECT); 1=ICLR_Z_CLR (CLR)
0x18BC QDIR ro — Count Direction Register
  [0] QDIR_DIR — Direction of count
    0=QDIR_DIR_DOWN (DOWN); 1=QDIR_DIR_UP (UP)
